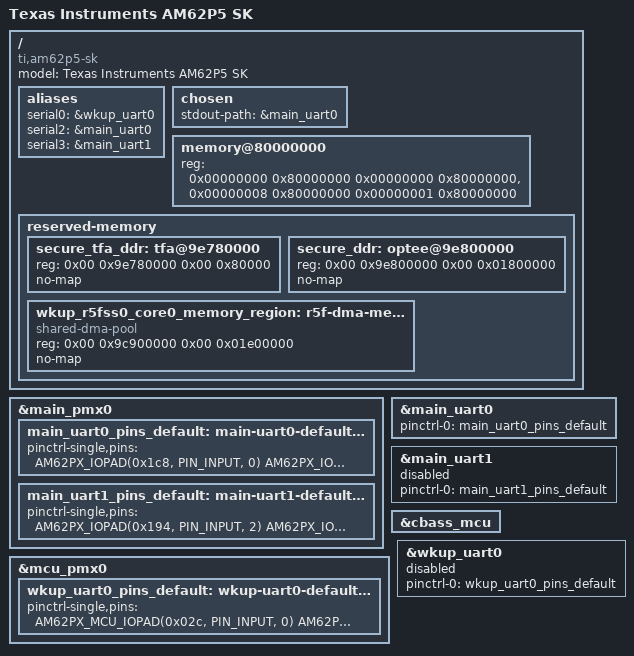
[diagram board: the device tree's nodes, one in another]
/dts-v1/;
#include "k3-am62p5.dtsi"
/ {
	compatible = "ti,am62p5-sk", "ti,am62p5";
	model = "Texas Instruments AM62P5 SK";
	aliases {
		serial0 = &wkup_uart0;
		serial2 = &main_uart0;
		serial3 = &main_uart1;
	};
	chosen {
		stdout-path = &main_uart0;
	};
	memory@80000000 {
		reg = <0x00000000 0x80000000 0x00000000 0x80000000>,
		      <0x00000008 0x80000000 0x00000001 0x80000000>;
		device_type = "memory";
	};
	reserved-memory {
		#address-cells = <2>;
		#size-cells = <2>;
		ranges;
		secure_tfa_ddr: tfa@9e780000 {
			reg = <0x00 0x9e780000 0x00 0x80000>;
			no-map;
		};
		secure_ddr: optee@9e800000 {
			reg = <0x00 0x9e800000 0x00 0x01800000>;  
			no-map;
		};
		wkup_r5fss0_core0_memory_region: r5f-dma-memory@9c900000 {
			compatible = "shared-dma-pool";
			reg = <0x00 0x9c900000 0x00 0x01e00000>;
			no-map;
		};
	};
};
&main_pmx0 {
	main_uart0_pins_default: main-uart0-default-pins {
		bootph-all;
		pinctrl-single,pins = <
			AM62PX_IOPAD(0x1c8, PIN_INPUT, 0)	 
			AM62PX_IOPAD(0x1cc, PIN_OUTPUT, 0)	 
			AM62PX_IOPAD(0x1d0, PIN_INPUT, 0)	 
			AM62PX_IOPAD(0x1d4, PIN_OUTPUT, 0)	 
		>;
	};
	main_uart1_pins_default: main-uart1-default-pins {
		bootph-all;
		pinctrl-single,pins = <
			AM62PX_IOPAD(0x194, PIN_INPUT, 2)	 
			AM62PX_IOPAD(0x198, PIN_OUTPUT, 2)	 
			AM62PX_IOPAD(0x1ac, PIN_INPUT, 2)	 
			AM62PX_IOPAD(0x1b0, PIN_OUTPUT, 2)	 
		>;
	};
};
&main_uart0 {
	bootph-all;
	pinctrl-names = "default";
	pinctrl-0 = <&main_uart0_pins_default>;
	status = "okay";
};
&main_uart1 {
	pinctrl-names = "default";
	pinctrl-0 = <&main_uart1_pins_default>;
	status = "reserved";
};
&cbass_mcu {
	bootph-all;
};
&mcu_pmx0 {
	bootph-all;
	wkup_uart0_pins_default: wkup-uart0-default-pins {
		bootph-all;
		pinctrl-single,pins = <
			AM62PX_MCU_IOPAD(0x02c, PIN_INPUT, 0)	 
			AM62PX_MCU_IOPAD(0x030, PIN_OUTPUT, 0)	 
			AM62PX_MCU_IOPAD(0x024, PIN_INPUT, 0)	 
			AM62PX_MCU_IOPAD(0x028, PIN_OUTPUT, 0)	 
		>;
	};
};
&wkup_uart0 {
	bootph-all;
	pinctrl-names = "default";
	pinctrl-0 = <&wkup_uart0_pins_default>;
	status = "reserved";
};
